# WKUP_CTRL_MMR0_CFG0 register map
Vendor: Texas Instruments
Registers are 32-bit, read-write, reset 0x0 unless marked. A register's access mark holds for its fields unless they carry their own. Offsets are as the file gives them; [hi:lo] are bit positions; {n}, {i} and the like mark numbered series.

## WKUP_CTRL_MMR0_CFG0 (part 2 of 2)
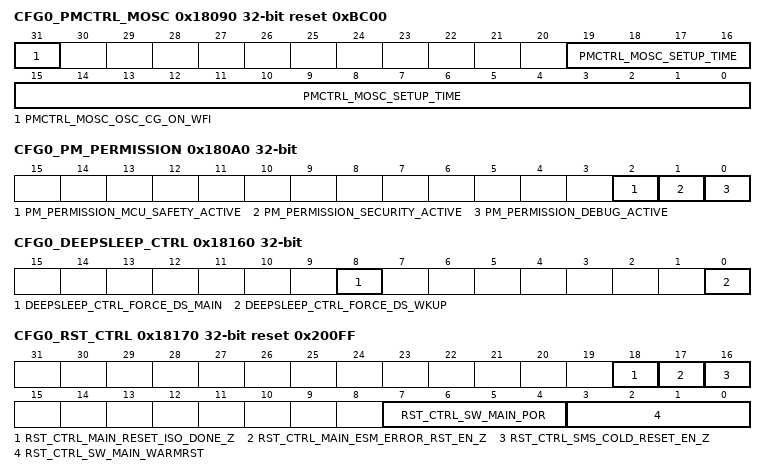
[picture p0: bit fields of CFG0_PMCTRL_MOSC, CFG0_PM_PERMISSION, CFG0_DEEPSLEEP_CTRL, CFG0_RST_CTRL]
0x18090 CFG0_PMCTRL_MOSC reset 0xBC00
  [31] PMCTRL_MOSC_OSC_CG_ON_WFI — When set by Device Manager - the soc clock gating logic will gate the device manager clock once Device Manager has entered the WFI state. (Note: this was named osc_cg_dis but name didn't match function)
  [19:0] PMCTRL_MOSC_SETUP_TIME — Keep the main oscillator clock gates for the number of HFOSC clock cycles This is the time it takes to stabilize the clock source supplier (i.e. Main Oscillator)
0x18098 CFG0_PM_MISC_STATUS ro
  [1:0] PM_MISC_STATUS_OSC_CG_STAT — Reflects the status of the request to clock-gate HF oscillator via MMR PMCTRL_MOSCundefined. 11: osc_cgen_req = '0' & osc_cgen_ack = '1' 10: osc_cgen_req = '1' & osc_cgen_ack = '0' 01: osc_cgen_req = '0' & osc_cgen_ack = '0' 00: osc_cgen_req = '1' & osc_cgen_ack = '1'
0x1809C CFG0_PMCTRL_IO_GLB
  [1:0] PMCTRL_IO_GLB_DSEN_QUALIFIED — To dsen_qualified signal generation logic for daisychain[1:0] logic. Used to control I/O buffer ouput and output activate during deepsleep mode. See IO Integration spec for detail.
0x180A0 CFG0_PM_PERMISSION ro
  [2] PM_PERMISSION_MCU_SAFETY_ACTIVE — Read Only - Reads return a 1 when am62_mcu_ctrl_mmr.wkup_0.RST_MAGIC_WORD_mcu_magic_word_ipcfg[31:0] != 32'h0. When 1, indicates that the MCU is blocking reset and also deep sleep entry.
  [1] PM_PERMISSION_SECURITY_ACTIVE — Read Only - Reads return the value of ms.main_0.sms_iopm_pmpermission_security_active. When 1, indicates that SMS is blocking deep sleep entry.
  [0] PM_PERMISSION_DEBUG_ACTIVE — Read Only - Returns a 1 when IceMelter is blocking deep sleep entry.
0x18160 CFG0_DEEPSLEEP_CTRL
  [8] DEEPSLEEP_CTRL_FORCE_DS_MAIN — Force all MAIN IOs into deepsleep mode when set
  [0] DEEPSLEEP_CTRL_FORCE_DS_WKUP — Force all WKUP IOs into deepsleep mode when set
0x18170 CFG0_RST_CTRL reset 0x200FF
  [18] RST_CTRL_MAIN_RESET_ISO_DONE_Z — Main Domain CPUs can set this bit to block warm reset in the main domain which is useful when the Main domain may be accessing main domain resources (peripherals, memory..). In this case, the main domain cpus will be notified via an interrupt that there is an outstanding warm reset request for the main domain. Once notified, Main needs to finish any outstanding operations in has with main domain resources and then clear this bit. After this bit is cleared, the main domain warm reset will unblocked and the warm reset sequence may continue. 0 - Reset of Main Domain is not Blocked by Main Domain 1 - Reset of Main Domain is Blocked by Main Domain
  [17] RST_CTRL_MAIN_ESM_ERROR_RST_EN_Z — Deactivate Reset of Main by ESM 0 - Activated 1 - Deactivated
  [16] RST_CTRL_SMS_COLD_RESET_EN_Z — Deactivate Reset of Main by SMS 0 - Activated 1 - Deactivated
  [7:4] RST_CTRL_SW_MAIN_POR — Causes Main Domain Power On Reset when set to 4'b0110, Bits will reset to 4'b1111
  [3:0] RST_CTRL_SW_MAIN_WARMRST — Causes Main Domain Warm Reset when set to 4'b0110, Bits will reset to 4'b1111
0x18174 CFG0_RST_STAT ro
  [0] RST_STAT_MCU_RESET_ISO_DONE_Z — is an outstanding warm reset request for the main domain. Once notified, MCU needs to finish any outstanding
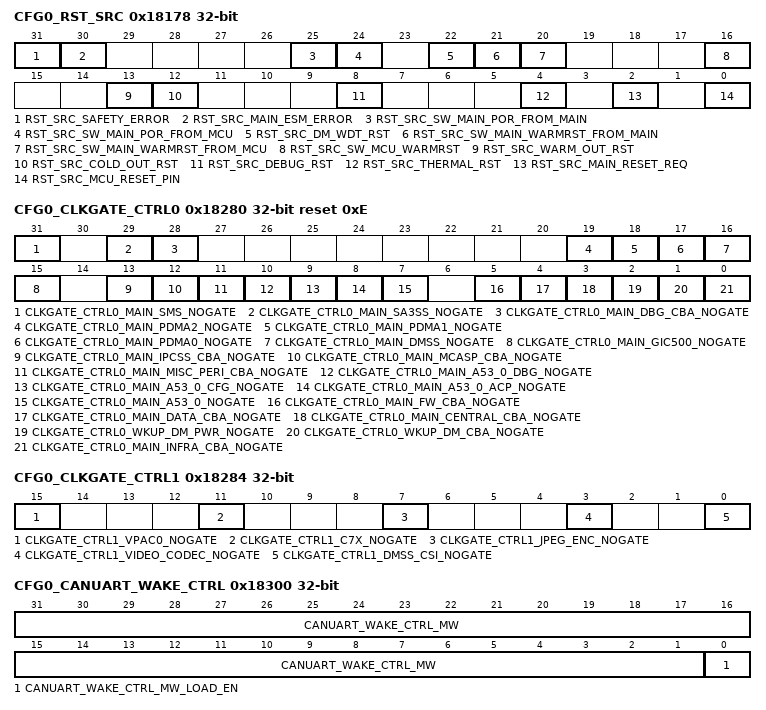
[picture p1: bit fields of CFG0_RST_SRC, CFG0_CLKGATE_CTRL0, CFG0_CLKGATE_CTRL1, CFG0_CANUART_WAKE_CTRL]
0x18178 CFG0_RST_SRC ro
  [31] RST_SRC_SAFETY_ERROR — Reset Caused by MCU ESM Error
  [30] RST_SRC_MAIN_ESM_ERROR — Reset Caused by Main ESM Error
  [25] RST_SRC_SW_MAIN_POR_FROM_MAIN — Software Main Power On Reset From MAIN CTRL MMR
  [24] RST_SRC_SW_MAIN_POR_FROM_MCU — Software Main Power On Reset From MCU CTRL MMR
  [22] RST_SRC_DM_WDT_RST — Watchdog Initiated Reset
  [21] RST_SRC_SW_MAIN_WARMRST_FROM_MAIN — Software Main Warm Reset from MAIN CTRL MMR
  [20] RST_SRC_SW_MAIN_WARMRST_FROM_MCU — Software Main Warm Reset From MCU CTRL MMR
  [16] RST_SRC_SW_MCU_WARMRST — Software Warm Reset
  [13] RST_SRC_WARM_OUT_RST — SMS Warm Reset
  [12] RST_SRC_COLD_OUT_RST — SMS Cold Reset
  [8] RST_SRC_DEBUG_RST — Debug Subsystem Initiated Reset
  [4] RST_SRC_THERMAL_RST — Thermal Reset
  [2] RST_SRC_MAIN_RESET_REQ — Main Reset Pin
  [0] RST_SRC_MCU_RESET_PIN — Rest Caused by MCU Reset Pin
0x1817C CFG0_RST_MAGIC_WORD ro
  [31:0] RST_MAGIC_WORD_MCU_MAGIC_WORD — Magic Word Indicating Status of MCU Subsystem Boot
0x18180 CFG0_WKUP0_EN
  [31:0] WKUP0_EN_WKUPEN — Activates Wakeup from: b0 - WKUP I2C0 b1 - WKUP USART0 b2 - MCU GPIO0 b3 - DEBUG (IceMelter) b4 - Reserved b5 - WKUP DMTIMER0 b6 - WKUP DMTIMER1 b7 - WKUP RTC b8 - Main RESET_REQz b9 - USB0 In Band b10 - USB1 In Band b16 - MAIN IO Daisy Chain b17 - MCU IO Daisy Chain b18 - CANUART IO Daisy Chain
0x18280 CFG0_CLKGATE_CTRL0 reset 0xE
  [31] CLKGATE_CTRL0_MAIN_SMS_NOGATE — MAIN domain SMS (pwr_dis_nogate) clock gate deactivate. 0 - Clocks are gated on idle for power savings 1 - Clocks are not gated on idle, power saving deactivated
  [29] CLKGATE_CTRL0_MAIN_SA3SS_NOGATE — MAIN domain SA3SS clock gate deactivate. 0 - Clocks are gated on idle for power savings 1 - Clocks are not gated on idle, power saving deactivated
  [28] CLKGATE_CTRL0_MAIN_DBG_CBA_NOGATE — MAIN domain Debug CBA (main_dbg_cba)clock gate deactivate. 0 - Clocks are gated on idle for power savings 1 - Clocks are not gated on idle, power saving deactivated
  [19] CLKGATE_CTRL0_MAIN_PDMA2_NOGATE — MAIN domain PDMA2 (pwr_dis_nogate) clock gate deactivate. 0 - Clocks are gated on idle for power savings 1 - Clocks are not gated on idle, power saving deactivated
  [18] CLKGATE_CTRL0_MAIN_PDMA1_NOGATE — MAIN domain PDMA1 (pwr_dis_nogate) clock gate deactivate. 0 - Clocks are gated on idle for power savings 1 - Clocks are not gated on idle, power saving deactivated
  [17] CLKGATE_CTRL0_MAIN_PDMA0_NOGATE — MAIN domain PDMA0 (pwr_dis_nogate) clock gate deactivate. 0 - Clocks are gated on idle for power savings 1 - Clocks are not gated on idle, power saving deactivated
  [16] CLKGATE_CTRL0_MAIN_DMSS_NOGATE — MAIN domain DMSS (pwr_dis_nogate) clock gate deactivate. 0 - Clocks are gated on idle for power savings 1 - Clocks are not gated on idle, power saving deactivated
  [15] CLKGATE_CTRL0_MAIN_GIC500_NOGATE — MAIN A53SS0 (gic500_1_2) clock gate deactivate. 0 - Clocks are gated on idle for power savings 1 - Clocks are not gated on idle, power saving deactivated
  [13] CLKGATE_CTRL0_MAIN_IPCSS_CBA_NOGATE — MAIN domain Infrastructure bus (main_ipcss_cbass) clock gate deactivate. 0 - Clocks are gated on idle for power savings 1 - Clocks are not gated on idle, power saving deactivated
  [12] CLKGATE_CTRL0_MAIN_MCASP_CBA_NOGATE — MAIN domain Infrastructure bus (main_mcasp_cbass) clock gate deactivate. 0 - Clocks are gated on idle for power savings 1 - Clocks are not gated on idle, power saving deactivated
  [11] CLKGATE_CTRL0_MAIN_MISC_PERI_CBA_NOGATE — MAIN domain Infrastructure bus (main_misc_peri_cbass) clock gate deactivate. 0 - Clocks are gated on idle for power savings 1 - Clocks are not gated on idle, power saving deactivated
  [10] CLKGATE_CTRL0_MAIN_A53_0_DBG_NOGATE — MAIN A53SS0 Debug Port clock gate deactivate. 0 - Clocks are gated on idle for power savings 1 - Clocks are not gated on idle, power saving deactivated
  [9] CLKGATE_CTRL0_MAIN_A53_0_CFG_NOGATE — MAIN A53SS0 Configuration Port clock gate deactivate. 0 - Clocks are gated on idle for power savings 1 - Clocks are not gated on idle, power saving deactivated
  [8] CLKGATE_CTRL0_MAIN_A53_0_ACP_NOGATE — MAIN A53SS0 ACP clock gate deactivate. 0 - Clocks are gated on idle for power savings 1 - Clocks are not gated on idle, power saving deactivated
  [7] CLKGATE_CTRL0_MAIN_A53_0_NOGATE — MAIN A53SS0 clock gate deactivate. 0 - Clocks are gated on idle for power savings 1 - Clocks are not gated on idle, power saving deactivated
  [5] CLKGATE_CTRL0_MAIN_FW_CBA_NOGATE — MAIN domain datal bus (main_fw_cbass) clock gate deactivate. 0 - Clocks are gated on idle for power savings 1 - Clocks are not gated on idle, power saving deactivated
  [4] CLKGATE_CTRL0_MAIN_DATA_CBA_NOGATE — MAIN domain data bus (main_cbass) clock gate deactivate. 0 - Clocks are gated on idle for power savings 1 - Clocks are not gated on idle, power saving deactivated
  [3] CLKGATE_CTRL0_MAIN_CENTRAL_CBA_NOGATE — WKUP domain Infrastructure ECC aggregator(wkup_safe_ecc_aggr) clock gate deactivate. 0 - Clocks are gated on idle for power savings 1 - Clocks are not gated on idle, power saving deactivated
  [2] CLKGATE_CTRL0_WKUP_DM_PWR_NOGATE — WKUP domain Device Manager (wkup_dm_pwr_nogate) clock gate deactivate. 0 - Clocks are gated on idle for power savings 1 - Clocks are not gated on idle, power saving deactivated
  [1] CLKGATE_CTRL0_WKUP_DM_CBA_NOGATE — WKUP domain device manager CBA clock gate deactivate. 0 - Clocks are gated on idle for power savings 1 - Clocks are not gated on idle, power saving deactivated
  [0] CLKGATE_CTRL0_MAIN_INFRA_CBA_NOGATE — MAIN domain Infrastructure bus (main_infra_cbass and psc_fw_ch_br) clock gate deactivate. 0 - Clocks are gated on idle for power savings 1 - Clocks are not gated on idle, power saving deactivated
0x18284 CFG0_CLKGATE_CTRL1
  [15] CLKGATE_CTRL1_VPAC0_NOGATE — VPAC0 clock gate deactivate. 0 - Clocks are gated on idle for power savings 1 - Clocks are not gated on idle, power saving deactivated
  [11] CLKGATE_CTRL1_C7X_NOGATE — C7x clock gate deactivate. 0 - Clocks are gated on idle for power savings 1 - Clocks are not gated on idle, power saving deactivated
  [7] CLKGATE_CTRL1_JPEG_ENC_NOGATE — JPEG Encoder clock gate deactivate. 0 - Clocks are gated on idle for power savings 1 - Clocks are not gated on idle, power saving deactivated
  [3] CLKGATE_CTRL1_VIDEO_CODEC_NOGATE — VIDEO CODEC clock gate deactivate. 0 - Clocks are gated on idle for power savings 1 - Clocks are not gated on idle, power saving deactivated
  [0] CLKGATE_CTRL1_DMSS_CSI_NOGATE — DMSS_CSI clock gate deactivate. 0 - Clocks are gated on idle for power savings 1 - Clocks are not gated on idle, power saving deactivated
0x18300 CFG0_CANUART_WAKE_CTRL
  [31:1] CANUART_WAKE_CTRL_MW — CANUART IO magic word. This 31-bit value that activates placing of the CANUART I/Os into isolation for daisy-chain wakeup operation. The Upper 8 bits are software defined. The lower 23 bits are checked by hardware: - 0x5AAAAA - Magic word value to activate isolation whenqualified with mw_load bit - Others - Any other value will prevent isolation when mw_loadtransitions from 0 to 1
  [0] CANUART_WAKE_CTRL_MW_LOAD_EN — Magic word load activate Setting this bit to 1 loads and locks the mw field for CANUART IO isolation. If the mw field matches the magicword value then the value is latched into the CANUART IO voltage domain and CANUART IO isolation is activated. 0 - Unlock and do not load mw value for comparison 1 - Load and lock mw for magic word value comparison
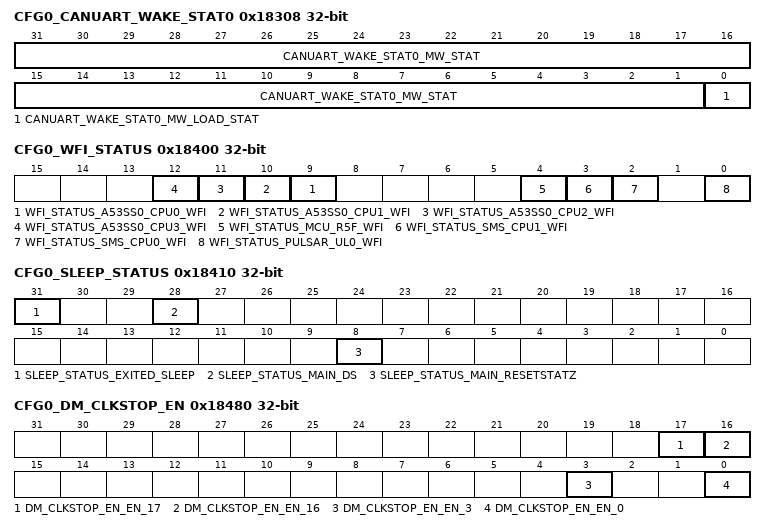
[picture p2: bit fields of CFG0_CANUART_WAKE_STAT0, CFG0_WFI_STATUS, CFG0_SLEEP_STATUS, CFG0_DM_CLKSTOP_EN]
0x18308 CFG0_CANUART_WAKE_STAT0 ro
  [31:1] CANUART_WAKE_STAT0_MW_STAT — CANUART magic word status Indicates the latched value of the mw field.
  [0] CANUART_WAKE_STAT0_MW_LOAD_STAT — Magic word load status. Indicates the latched value of the mw_load_en bit
0x1830C CFG0_CANUART_WAKE_STAT1 ro
  [0] CANUART_WAKE_STAT1_CANUART_IO_MODE — Indicates if CANUART IO wakeup mode is activated. 0 - Not activated (load_en not set or mw doesn't match magic word) 1 - CANUART IO mode activated
0x18310 CFG0_CANUART_WAKE_OFF_MODE
  [31:0] CANUART_WAKE_OFF_MODE_MW — magic word
0x18318 CFG0_CANUART_WAKE_OFF_MODE_STAT ro
  [31:0] CANUART_WAKE_OFF_MODE_STAT_MW — returned magic word
0x18320 CFG0_CANUART_WAKE_RESUME_KEY
  [31:0] KEYVAL — key value
0x18340 CFG0_CANUART_WAKE_RESUME_KEY_STAT ro
  [31:0] KEYVAL — returned key value
0x18400 CFG0_WFI_STATUS ro
  [n+9] WFI_STATUS_A53SS0_CPU{n}_WFI (n=0..3) — WFI status of A53SS0 CPU{n}
  [4] WFI_STATUS_MCU_R5F_WFI — WFI status of MCU Cortex R5F
  [3] WFI_STATUS_SMS_CPU1_WFI — WFI status of SMS Cortex M4F1
  [2] WFI_STATUS_SMS_CPU0_WFI — WFI status of SMS Cortex M4F0
  [0] WFI_STATUS_PULSAR_UL0_WFI — WFI status of Device Manager Cortex R5F
0x18410 CFG0_SLEEP_STATUS access not given
  [31] SLEEP_STATUS_EXITED_SLEEP — Set when the HFXOSC clock gate is activated (rising edge capture of OSC_CG_ACK). To be read and cleared by DM after exiting WFI as a status signal distinguishing the case where WFI was entered and the clock was stopped, then exited with a wakeup (this bit will be set) from the case where an interrupt or other event caused the WFI sequence to stop and the HFXOSC was never stopped. (access R/W1TC)
  [28] SLEEP_STATUS_MAIN_DS — Set when the main domain deep sleep power on reset / power domain off is activated. (rising edge detect of am62_wkup_ctrl_mmr.wkup_0.DS_MAIN_por_pdoff_ft_out_ipcfg). This will be checked by the ROM on TIFS upon exiting from reset to determine if it is a power on reset or exiting deep sleep. (access R/W1TC)
  [8] SLEEP_STATUS_MAIN_RESETSTATZ ro — Reflects the status of the main domain resetz signal Field values (others are reserved): 1'b0 - Main Domain In Reset 1'b1 - Main Domain Out of Reset
0x18418 CFG0_DS_MAGIC_WORD
  [31:0] DS_MAGIC_WORD_DS_MAGIC_WORD — Magic Word Indicating State of Deep Sleep
0x18420 CFG0_DS_MAIN reset 0xF
  [3:0] DS_MAIN_POR_PDOFF — Signal Puts main SMS, DebugSS and MainIP Power Domains into Power Off state, and asserts Main Power On Reset. Field values (others are reserved): 4'b0110 - Off 4'b1111 - On
0x18440 CFG0_DS_DM_RESET reset 0xF
  [3:0] DS_DM_RESET_MASK — Signal used to mask main domain resets from Device Manager / Wakeup and MCU Ips Field values (others are reserved): 4'b0110 - Masked 4'b1111 - UnMasked
0x18460 CFG0_DS_USB0_RESET reset 0xF
  [3:0] DS_USB0_RESET_MASK — Signal used to block reset to the USBSS0 Field values (others are reserved): 4'b0110 - Masked 4'b1111 - UnMasked
0x18464 CFG0_DS_USB1_RESET reset 0xF
  [3:0] DS_USB1_RESET_MASK — Signal used to block reset to the USBSS1 Field values (others are reserved): 4'b0110 - Masked 4'b1111 - UnMasked
0x18480 CFG0_DM_CLKSTOP_EN
  [17] DM_CLKSTOP_EN_EN_17 — WKUP DMTIMER1 Participation in Clockstop Req Group Field values (others are reserved): 1'b0 - Not Participating in Clockstop Override Group. DM_CLKSTOP_ACK.17 always reads '1' 1'b1 - Participating in Clockstop Override Group. DM_CLKSTOP_ACK.17 reflects the IP clockstop_ack
  [16] DM_CLKSTOP_EN_EN_16 — WKUP DMTIMER0 Participation in Clockstop Req Group Field values (others are reserved): 1'b0 - Not Participating in Clockstop Override Group. DM_CLKSTOP_ACK.16 always reads '1' 1'b1 - Participating in Clockstop Override Group. DM_CLKSTOP_ACK.16 reflects the IP clockstop_ack
  [3] DM_CLKSTOP_EN_EN_3 — WKUP UART0 Participation in Clockstop Req Group Field values (others are reserved): 1'b0 - Not Participating in Clockstop Override Group. DM_CLKSTOP_ACK.3 always reads '1' 1'b1 - Participating in Clockstop Override Group. DM_CLKSTOP_ACK.3 reflects the IP clockstop_ack
  [0] DM_CLKSTOP_EN_EN_0 — WKUP I2C0 Participation in Clockstop Req Group Field values (others are reserved): 1'b0 - Not Participating in Clockstop Override Group. DM_CLKSTOP_ACK.0 always reads '1' 1'b1 - Participating in Clockstop Override Group. DM_CLKSTOP_ACK.0 reflects the IP clockstop_ack
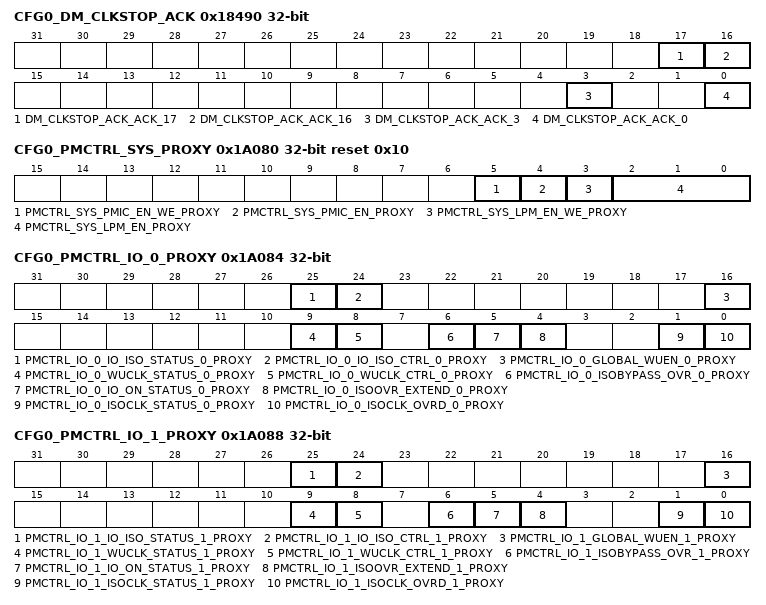
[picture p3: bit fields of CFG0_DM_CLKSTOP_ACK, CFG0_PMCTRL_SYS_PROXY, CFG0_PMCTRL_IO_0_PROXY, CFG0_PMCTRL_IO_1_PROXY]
0x18490 CFG0_DM_CLKSTOP_ACK ro
  [17] DM_CLKSTOP_ACK_ACK_17 — WKUP DMTIMER1 Clockstop Ack Status Field values (others are reserved): 1'b0 - IP is Participating in Clockstop Override Group, and IP clockstop_ack is 0 1'b1 - IP Is either not Participating in Clockstop Override Group, or IP has returned IP clockstop_ack
  [16] DM_CLKSTOP_ACK_ACK_16 — WKUP DMTIMER0 Clockstop Ack Status Field values (others are reserved): 1'b0 - IP is Participating in Clockstop Override Group, and IP clockstop_ack is 0 1'b1 - IP Is either not Participating in Clockstop Override Group, or IP has returned IP clockstop_ack
  [3] DM_CLKSTOP_ACK_ACK_3 — WKUP UART0 Clockstop Ack Status Field values (others are reserved): 1'b0 - IP is Participating in Clockstop Override Group, and IP clockstop_ack is 0 1'b1 - IP Is either not Participating in Clockstop Override Group, or IP has returned IP clockstop_ack
  [0] DM_CLKSTOP_ACK_ACK_0 — WKUP I2C0 Clockstop Ack Status Field values (others are reserved): 1'b0 - IP is Participating in Clockstop Override Group, and IP clockstop_ack is 0 1'b1 - IP Is either not Participating in Clockstop Override Group, or IP has returned IP clockstop_ack
0x184A0 CFG0_DM_GRP_CLKSTOP_REQ
  [0] DM_GRP_CLKSTOP_REQ_REQ — Assertion of Clockstop Req to IPs participating in Clockstop Req Group Field values (others are reserved): 1'b0 - Deassert CLKSTOP Req to all IPs participating in Clockstop Override Group 1'b1 - Assert CLKSTOP Req to all IPs participating in Clockstop Override Group
0x184A4 CFG0_DM_GRP_CLKSTOP_ACK ro
  [0] DM_GRP_CLKSTOP_ACK_ACK — Status of IPs Participating in Clockstop Ack Group. If DM_CLKSTOP_EN is 0 (no IPs participating) this bit always reads 1. Field values (others are reserved): 1'b0 - At least one IP participating in Clockstop Override has not returned Ack 1'b1 - All IPs that are participating in Clockstop Override have returned Ack
0x18500 CFG0_DEVICE_TYPE ro
  [7:4] DEVICE_TYPE_SMS_DEV_TYPE
{0x19100+4i} CFG0_CLAIMREG_P6_R{i}_READONLY ro (i=0..10)
  [31:0] CLAIMREG_P6_R{i}_READONLY — Claim bits for Partition 6
0x1A040 CFG0_FW_CTRL_OUT0_PROXY
  [31:0] FW_CTRL_OUT0_FW_CTRL_OUT0_PROXY
0x1A044 CFG0_FW_CTRL_OUT0_SET_PROXY access not given reset not defined
0x1A048 CFG0_FW_CTRL_OUT0_CLR_PROXY access not given reset not defined
0x1A04C CFG0_FW_STS_IN0_PROXY access not given reset not defined
0x1A050 CFG0_FW_CTRL_OUT1_PROXY access not given reset not defined
0x1A054 CFG0_FW_CTRL_OUT1_SET_PROXY access not given reset not defined
0x1A058 CFG0_FW_CTRL_OUT1_CLR_PROXY access not given reset not defined
0x1A05C CFG0_FW_STS_IN1_PROXY access not given reset not defined
0x1A080 CFG0_PMCTRL_SYS_PROXY reset 0x10
  [5] PMCTRL_SYS_PMIC_EN_WE_PROXY — Unused Field - Value is Don't Care
  [4] PMCTRL_SYS_PMIC_EN_PROXY — Controls state of PMIC_LPM_EN_OUT when LPM_EN[2:0] is 000
  [3] PMCTRL_SYS_LPM_EN_WE_PROXY — Unused Field - Value is Don't Care
  [2:0] PMCTRL_SYS_LPM_EN_PROXY — Controls whether PMIC_LPM_EN_OUT is driven by the pmic_en bit, or by deep sleep logic. Field values (others are reserved): 3'b000 - PMIC_LPM_EN_OUT controlled by pmic_en bit. 3'b101 - PMIC_LPM_EN_OUT controlled by DeepSleep Logic
0x1A084 CFG0_PMCTRL_IO_0_PROXY access per field
  [25] PMCTRL_IO_0_IO_ISO_STATUS_0_PROXY ro — IO ISO Status. Read 0: IO isolation not active. Read 1: IO isolation active. Reflects value of DM input port io_isoack coming back from IO pad ring.
  [24] PMCTRL_IO_0_IO_ISO_CTRL_0_PROXY rw — IO ISO control. Writing this bit to 1 will kick off IO isolation.
  [16] PMCTRL_IO_0_GLOBAL_WUEN_0_PROXY rw — Global IO wakeup activate. This is a gating condition to all individual IO WUEN coming from control module. Gating is done in the Spinner logic. 0:All individual IO WUEN are gated in the Spinner logic (override to 0). 1: All individual IO WUEN from control module are going to Ios. Map to DM input port io_globalwkupen
  [9] PMCTRL_IO_0_WUCLK_STATUS_0_PROXY ro — Reflects value of DM input port io_wuclkack coming back from IO pad ring.
  [8] PMCTRL_IO_0_WUCLK_CTRL_0_PROXY rw — Direct control on WUCLKIN signal to IO pad ring.0:WUCLKIN signal is driven to 0.IO wakeup daisy chain is functional as well as IO whose wakeup feature is activated. 1:WUCLKIN signal is driven to 1. IO wakeup daisy chain is reset and is latching current pad states and WUEN inputs.
  [6] PMCTRL_IO_0_ISOBYPASS_OVR_0_PROXY rw — This MMR bit drives directly DM output port io_isobypassundefined.
  [5] PMCTRL_IO_0_IO_ON_STATUS_0_PROXY ro — Gives the functional status of the IO ring. Read 0: Part or all of the Ios are not in the ON state that is are in isolation state. Read 1: All Ios are in the ON state. io_on_status = assign 1 if (io_iso == 0 & io_isoack==0 & io_iso_clk == 0 & io_isoclk_ack = 0 ) else 0;
  [4] PMCTRL_IO_0_ISOOVR_EXTEND_0_PROXY rw — This drives the SOC chain ISO-OVERRIDE global control. This bit drives directly the DM output port io_isoovrundefined. At the SOC level it is used to activate when 1 or gate-off when 0, the individual ISOOR for each IO. This operates as a global activate/deactivate for the individual IOs.Control for IO isolation extension. '0' IO isolation is not extended. Transition happens as soon as automatic restore is completed. '1' IO isolation is extended. The IOs whose ISOOVR bits have been individually set in their PADCFG MMRs will all get its IO isolation extended beyond the point when the initial IO daisy chain isolation is released.
  [1] PMCTRL_IO_0_ISOCLK_STATUS_0_PROXY ro — Reflects value of DM input port io_isoclkack coming back from IO pad ring.
  [0] PMCTRL_IO_0_ISOCLK_OVRD_0_PROXY rw — Override control on ISOCLKIN signal to IO pad ring. When not overridden this signal is controlled by hardware only. 0 ISOCLKIN signal is not override. 1 ISOCLKIN signal is overridden to active value ('1').
0x1A088 CFG0_PMCTRL_IO_1_PROXY access per field
  [25] PMCTRL_IO_1_IO_ISO_STATUS_1_PROXY ro — IO ISO Status. Read 0: IO isolation not active. Read 1: IO isolation active. Reflects value of DM input port io_isoack coming back from IO pad ring.
  [24] PMCTRL_IO_1_IO_ISO_CTRL_1_PROXY rw — IO ISO control. Writing this bit to 1 will kick off IO isolation.
  [16] PMCTRL_IO_1_GLOBAL_WUEN_1_PROXY rw — Global IO wakeup activate. This is a gating condition to all individual IO WUEN coming from control module. Gating is done in the Spinner logic. 0:All individual IO WUEN are gated in the Spinner logic (override to 0). 1: All individual IO WUEN from control module are going to Ios. Map to DM input port io_globalwkupen
  [9] PMCTRL_IO_1_WUCLK_STATUS_1_PROXY ro — Reflects value of DM input port io_wuclkack coming back from IO pad ring.
  [8] PMCTRL_IO_1_WUCLK_CTRL_1_PROXY rw — Direct control on WUCLKIN signal to IO pad ring.0:WUCLKIN signal is driven to 0.IO wakeup daisy chain is functional as well as IO whose wakeup feature is activated. 1:WUCLKIN signal is driven to 1. IO wakeup daisy chain is reset and is latching current pad states and WUEN inputs.
  [6] PMCTRL_IO_1_ISOBYPASS_OVR_1_PROXY rw — This MMR bit drives directly DM output port io_isobypassundefined.
  [5] PMCTRL_IO_1_IO_ON_STATUS_1_PROXY ro — Gives the functional status of the IO ring. Read 0: Part or all of the Ios are not in the ON state that is are in isolation state. Read 1: All Ios are in the ON state. io_on_status = assign 1 if (io_iso == 0 & io_isoack==0 & io_iso_clk == 0 & io_isoclk_ack = 0 ) else 0;
  [4] PMCTRL_IO_1_ISOOVR_EXTEND_1_PROXY rw — This drives the SOC chain ISO-OVERRIDE global control. This bit drives directly the DM output port io_isoovrundefined. At the SOC level it is used to activate when 1 or gate-off when 0, the individual ISOOR for each IO. This operates as a global activate/deactivate for the individual IOs.Control for IO isolation extension. '0' IO isolation is not extended. Transition happens as soon as automatic restore is completed. '1' IO isolation is extended. The IOs whose ISOOVR bits have been individually set in their PADCFG MMRs will all get its IO isolation extended beyond the point when the initial IO daisy chain isolation is released.
  [1] PMCTRL_IO_1_ISOCLK_STATUS_1_PROXY ro — Reflects value of DM input port io_isoclkack coming back from IO pad ring.
  [0] PMCTRL_IO_1_ISOCLK_OVRD_1_PROXY rw — Override control on ISOCLKIN signal to IO pad ring. When not overridden this signal is controlled by hardware only. 0 ISOCLKIN signal is not override. 1 ISOCLKIN signal is overridden to active value ('1').
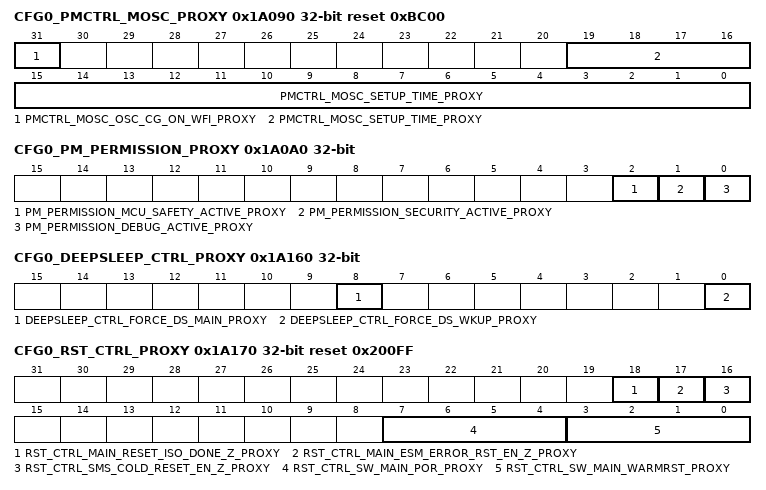
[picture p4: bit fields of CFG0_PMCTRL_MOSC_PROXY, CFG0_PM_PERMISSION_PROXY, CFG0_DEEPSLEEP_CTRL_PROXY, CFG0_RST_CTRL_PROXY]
0x1A090 CFG0_PMCTRL_MOSC_PROXY reset 0xBC00
  [31] PMCTRL_MOSC_OSC_CG_ON_WFI_PROXY — When set by Device Manager - the soc clock gating logic will gate the device manager clock once Device Manager has entered the WFI state. (Note: this was named osc_cg_dis but name didn't match function)
  [19:0] PMCTRL_MOSC_SETUP_TIME_PROXY — Keep the main oscillator clock gates for the number of HFOSC clock cycles This is the time it takes to stabilize the clock source supplier (i.e. Main Oscillator)
0x1A098 CFG0_PM_MISC_STATUS_PROXY ro
  [1:0] PM_MISC_STATUS_OSC_CG_STAT_PROXY — Reflects the status of the request to clock-gate HF oscillator via MMR PMCTRL_MOSCundefined. 11: osc_cgen_req = '0' & osc_cgen_ack = '1' 10: osc_cgen_req = '1' & osc_cgen_ack = '0' 01: osc_cgen_req = '0' & osc_cgen_ack = '0' 00: osc_cgen_req = '1' & osc_cgen_ack = '1'
0x1A09C CFG0_PMCTRL_IO_GLB_PROXY
  [1:0] PMCTRL_IO_GLB_DSEN_QUALIFIED_PROXY — To dsen_qualified signal generation logic for daisychain[1:0] logic. Used to control I/O buffer ouput and output activate during deepsleep mode. See IO Integration spec for detail.
0x1A0A0 CFG0_PM_PERMISSION_PROXY ro
  [2] PM_PERMISSION_MCU_SAFETY_ACTIVE_PROXY — Read Only - Reads return a 1 when am62_mcu_ctrl_mmr.wkup_0.RST_MAGIC_WORD_mcu_magic_word_ipcfg[31:0] != 32'h0. When 1, indicates that the MCU is blocking reset and also deep sleep entry.
  [1] PM_PERMISSION_SECURITY_ACTIVE_PROXY — Read Only - Reads return the value of ms.main_0.sms_iopm_pmpermission_security_active. When 1, indicates that SMS is blocking deep sleep entry.
  [0] PM_PERMISSION_DEBUG_ACTIVE_PROXY — Read Only - Returns a 1 when IceMelter is blocking deep sleep entry.
0x1A160 CFG0_DEEPSLEEP_CTRL_PROXY
  [8] DEEPSLEEP_CTRL_FORCE_DS_MAIN_PROXY — Force all MAIN IOs into deepsleep mode when set
  [0] DEEPSLEEP_CTRL_FORCE_DS_WKUP_PROXY — Force all WKUP IOs into deepsleep mode when set
0x1A170 CFG0_RST_CTRL_PROXY reset 0x200FF
  [18] RST_CTRL_MAIN_RESET_ISO_DONE_Z_PROXY — Main Domain CPUs can set this bit to block warm reset in the main domain which is useful when the Main domain may be accessing main domain resources (peripherals, memory..). In this case, the main domain cpus will be notified via an interrupt that there is an outstanding warm reset request for the main domain. Once notified, Main needs to finish any outstanding operations in has with main domain resources and then clear this bit. After this bit is cleared, the main domain warm reset will unblocked and the warm reset sequence may continue. 0 - Reset of Main Domain is not Blocked by Main Domain 1 - Reset of Main Domain is Blocked by Main Domain
  [17] RST_CTRL_MAIN_ESM_ERROR_RST_EN_Z_PROXY — Deactivate Reset of Main by ESM 0 - Activated 1 - Deactivated
  [16] RST_CTRL_SMS_COLD_RESET_EN_Z_PROXY — Deactivate Reset of Main by SMS 0 - Activated 1 - Deactivated
  [7:4] RST_CTRL_SW_MAIN_POR_PROXY — Causes Main Domain Power On Reset when set to 4'b0110, Bits will reset to 4'b1111
  [3:0] RST_CTRL_SW_MAIN_WARMRST_PROXY — Causes Main Domain Warm Reset when set to 4'b0110, Bits will reset to 4'b1111
0x1A174 CFG0_RST_STAT_PROXY ro
  [0] RST_STAT_MCU_RESET_ISO_DONE_Z_PROXY — is an outstanding warm reset request for the main domain. Once notified, MCU needs to finish any outstanding
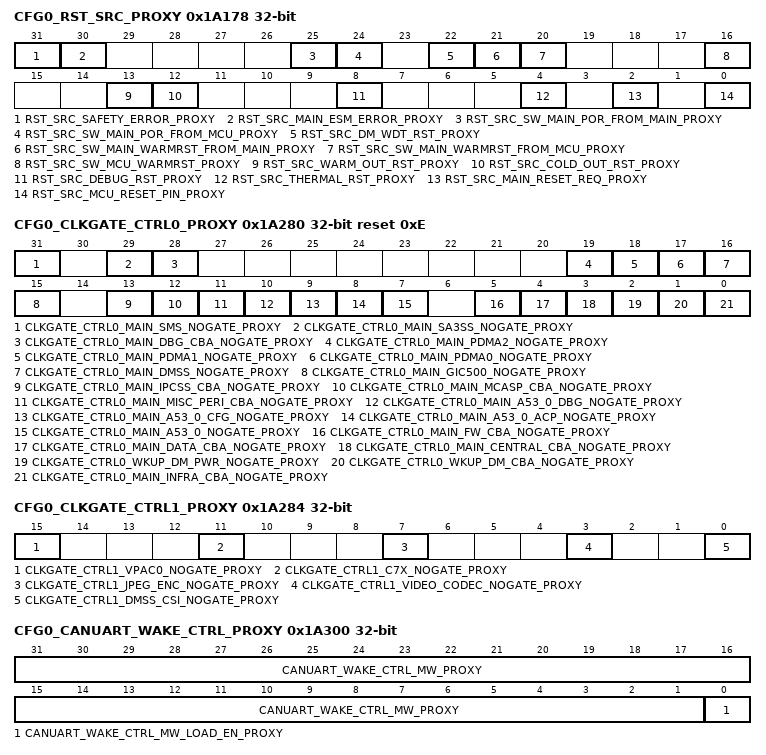
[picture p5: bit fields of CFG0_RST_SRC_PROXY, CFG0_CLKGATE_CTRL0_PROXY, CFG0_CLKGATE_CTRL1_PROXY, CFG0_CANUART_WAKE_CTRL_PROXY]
0x1A178 CFG0_RST_SRC_PROXY ro
  [31] RST_SRC_SAFETY_ERROR_PROXY — Reset Caused by MCU ESM Error
  [30] RST_SRC_MAIN_ESM_ERROR_PROXY — Reset Caused by Main ESM Error
  [25] RST_SRC_SW_MAIN_POR_FROM_MAIN_PROXY — Software Main Power On Reset From MAIN CTRL MMR
  [24] RST_SRC_SW_MAIN_POR_FROM_MCU_PROXY — Software Main Power On Reset From MCU CTRL MMR
  [22] RST_SRC_DM_WDT_RST_PROXY — Watchdog Initiated Reset
  [21] RST_SRC_SW_MAIN_WARMRST_FROM_MAIN_PROXY — Software Main Warm Reset from MAIN CTRL MMR
  [20] RST_SRC_SW_MAIN_WARMRST_FROM_MCU_PROXY — Software Main Warm Reset From MCU CTRL MMR
  [16] RST_SRC_SW_MCU_WARMRST_PROXY — Software Warm Reset
  [13] RST_SRC_WARM_OUT_RST_PROXY — SMS Warm Reset
  [12] RST_SRC_COLD_OUT_RST_PROXY — SMS Cold Reset
  [8] RST_SRC_DEBUG_RST_PROXY — Debug Subsystem Initiated Reset
  [4] RST_SRC_THERMAL_RST_PROXY — Thermal Reset
  [2] RST_SRC_MAIN_RESET_REQ_PROXY — Main Reset Pin
  [0] RST_SRC_MCU_RESET_PIN_PROXY — Rest Caused by MCU Reset Pin
0x1A17C CFG0_RST_MAGIC_WORD_PROXY ro
  [31:0] RST_MAGIC_WORD_MCU_MAGIC_WORD_PROXY — Magic Word Indicating Status of MCU Subsystem Boot
0x1A180 CFG0_WKUP0_EN_PROXY
  [31:0] WKUP0_EN_WKUPEN_PROXY — Activates Wakeup from: b0 - WKUP I2C0 b1 - WKUP USART0 b2 - MCU GPIO0 b3 - DEBUG (IceMelter) b4 - Reserved b5 - WKUP DMTIMER0 b6 - WKUP DMTIMER1 b7 - WKUP RTC b8 - Main RESET_REQz b9 - USB0 In Band b10 - USB1 In Band b16 - MAIN IO Daisy Chain b17 - MCU IO Daisy Chain b18 - CANUART IO Daisy Chain
0x1A280 CFG0_CLKGATE_CTRL0_PROXY reset 0xE
  [31] CLKGATE_CTRL0_MAIN_SMS_NOGATE_PROXY — MAIN domain SMS (pwr_dis_nogate) clock gate deactivate. 0 - Clocks are gated on idle for power savings 1 - Clocks are not gated on idle, power saving deactivated
  [29] CLKGATE_CTRL0_MAIN_SA3SS_NOGATE_PROXY — MAIN domain SA3SS clock gate deactivate. 0 - Clocks are gated on idle for power savings 1 - Clocks are not gated on idle, power saving deactivated
  [28] CLKGATE_CTRL0_MAIN_DBG_CBA_NOGATE_PROXY — MAIN domain Debug CBA (main_dbg_cba)clock gate deactivate. 0 - Clocks are gated on idle for power savings 1 - Clocks are not gated on idle, power saving deactivated
  [19] CLKGATE_CTRL0_MAIN_PDMA2_NOGATE_PROXY — MAIN domain PDMA2 (pwr_dis_nogate) clock gate deactivate. 0 - Clocks are gated on idle for power savings 1 - Clocks are not gated on idle, power saving deactivated
  [18] CLKGATE_CTRL0_MAIN_PDMA1_NOGATE_PROXY — MAIN domain PDMA1 (pwr_dis_nogate) clock gate deactivate. 0 - Clocks are gated on idle for power savings 1 - Clocks are not gated on idle, power saving deactivated
  [17] CLKGATE_CTRL0_MAIN_PDMA0_NOGATE_PROXY — MAIN domain PDMA0 (pwr_dis_nogate) clock gate deactivate. 0 - Clocks are gated on idle for power savings 1 - Clocks are not gated on idle, power saving deactivated
  [16] CLKGATE_CTRL0_MAIN_DMSS_NOGATE_PROXY — MAIN domain DMSS (pwr_dis_nogate) clock gate deactivate. 0 - Clocks are gated on idle for power savings 1 - Clocks are not gated on idle, power saving deactivated
  [15] CLKGATE_CTRL0_MAIN_GIC500_NOGATE_PROXY — MAIN A53SS0 (gic500_1_2) clock gate deactivate. 0 - Clocks are gated on idle for power savings 1 - Clocks are not gated on idle, power saving deactivated
  [13] CLKGATE_CTRL0_MAIN_IPCSS_CBA_NOGATE_PROXY — MAIN domain Infrastructure bus (main_ipcss_cbass) clock gate deactivate. 0 - Clocks are gated on idle for power savings 1 - Clocks are not gated on idle, power saving deactivated
  [12] CLKGATE_CTRL0_MAIN_MCASP_CBA_NOGATE_PROXY — MAIN domain Infrastructure bus (main_mcasp_cbass) clock gate deactivate. 0 - Clocks are gated on idle for power savings 1 - Clocks are not gated on idle, power saving deactivated
  [11] CLKGATE_CTRL0_MAIN_MISC_PERI_CBA_NOGATE_PROXY — MAIN domain Infrastructure bus (main_misc_peri_cbass) clock gate deactivate. 0 - Clocks are gated on idle for power savings 1 - Clocks are not gated on idle, power saving deactivated
  [10] CLKGATE_CTRL0_MAIN_A53_0_DBG_NOGATE_PROXY — MAIN A53SS0 Debug Port clock gate deactivate. 0 - Clocks are gated on idle for power savings 1 - Clocks are not gated on idle, power saving deactivated
  [9] CLKGATE_CTRL0_MAIN_A53_0_CFG_NOGATE_PROXY — MAIN A53SS0 Configuration Port clock gate deactivate. 0 - Clocks are gated on idle for power savings 1 - Clocks are not gated on idle, power saving deactivated
  [8] CLKGATE_CTRL0_MAIN_A53_0_ACP_NOGATE_PROXY — MAIN A53SS0 ACP clock gate deactivate. 0 - Clocks are gated on idle for power savings 1 - Clocks are not gated on idle, power saving deactivated
  [7] CLKGATE_CTRL0_MAIN_A53_0_NOGATE_PROXY — MAIN A53SS0 clock gate deactivate. 0 - Clocks are gated on idle for power savings 1 - Clocks are not gated on idle, power saving deactivated
  [5] CLKGATE_CTRL0_MAIN_FW_CBA_NOGATE_PROXY — MAIN domain datal bus (main_fw_cbass) clock gate deactivate. 0 - Clocks are gated on idle for power savings 1 - Clocks are not gated on idle, power saving deactivated
  [4] CLKGATE_CTRL0_MAIN_DATA_CBA_NOGATE_PROXY — MAIN domain data bus (main_cbass) clock gate deactivate. 0 - Clocks are gated on idle for power savings 1 - Clocks are not gated on idle, power saving deactivated
  [3] CLKGATE_CTRL0_MAIN_CENTRAL_CBA_NOGATE_PROXY — WKUP domain Infrastructure ECC aggregator(wkup_safe_ecc_aggr) clock gate deactivate. 0 - Clocks are gated on idle for power savings 1 - Clocks are not gated on idle, power saving deactivated
  [2] CLKGATE_CTRL0_WKUP_DM_PWR_NOGATE_PROXY — WKUP domain Device Manager (wkup_dm_pwr_nogate) clock gate deactivate. 0 - Clocks are gated on idle for power savings 1 - Clocks are not gated on idle, power saving deactivated
  [1] CLKGATE_CTRL0_WKUP_DM_CBA_NOGATE_PROXY — WKUP domain device manager CBA clock gate deactivate. 0 - Clocks are gated on idle for power savings 1 - Clocks are not gated on idle, power saving deactivated
  [0] CLKGATE_CTRL0_MAIN_INFRA_CBA_NOGATE_PROXY — MAIN domain Infrastructure bus (main_infra_cbass and psc_fw_ch_br) clock gate deactivate. 0 - Clocks are gated on idle for power savings 1 - Clocks are not gated on idle, power saving deactivated
0x1A284 CFG0_CLKGATE_CTRL1_PROXY
  [15] CLKGATE_CTRL1_VPAC0_NOGATE_PROXY — VPAC0 clock gate deactivate. 0 - Clocks are gated on idle for power savings 1 - Clocks are not gated on idle, power saving deactivated
  [11] CLKGATE_CTRL1_C7X_NOGATE_PROXY — C7x clock gate deactivate. 0 - Clocks are gated on idle for power savings 1 - Clocks are not gated on idle, power saving deactivated
  [7] CLKGATE_CTRL1_JPEG_ENC_NOGATE_PROXY — JPEG Encoder clock gate deactivate. 0 - Clocks are gated on idle for power savings 1 - Clocks are not gated on idle, power saving deactivated
  [3] CLKGATE_CTRL1_VIDEO_CODEC_NOGATE_PROXY — VIDEO CODEC clock gate deactivate. 0 - Clocks are gated on idle for power savings 1 - Clocks are not gated on idle, power saving deactivated
  [0] CLKGATE_CTRL1_DMSS_CSI_NOGATE_PROXY — DMSS_CSI clock gate deactivate. 0 - Clocks are gated on idle for power savings 1 - Clocks are not gated on idle, power saving deactivated
0x1A300 CFG0_CANUART_WAKE_CTRL_PROXY
  [31:1] CANUART_WAKE_CTRL_MW_PROXY — CANUART IO magic word. This 31-bit value that activates placing of the CANUART I/Os into isolation for daisy-chain wakeup operation. The Upper 8 bits are software defined. The lower 23 bits are checked by hardware: - 0x5AAAAA - Magic word value to activate isolation whenqualified with mw_load bit - Others - Any other value will prevent isolation when mw_loadtransitions from 0 to 1
  [0] CANUART_WAKE_CTRL_MW_LOAD_EN_PROXY — Magic word load activate Setting this bit to 1 loads and locks the mw field for CANUART IO isolation. If the mw field matches the magicword value then the value is latched into the CANUART IO voltage domain and CANUART IO isolation is activated. 0 - Unlock and do not load mw value for comparison 1 - Load and lock mw for magic word value comparison
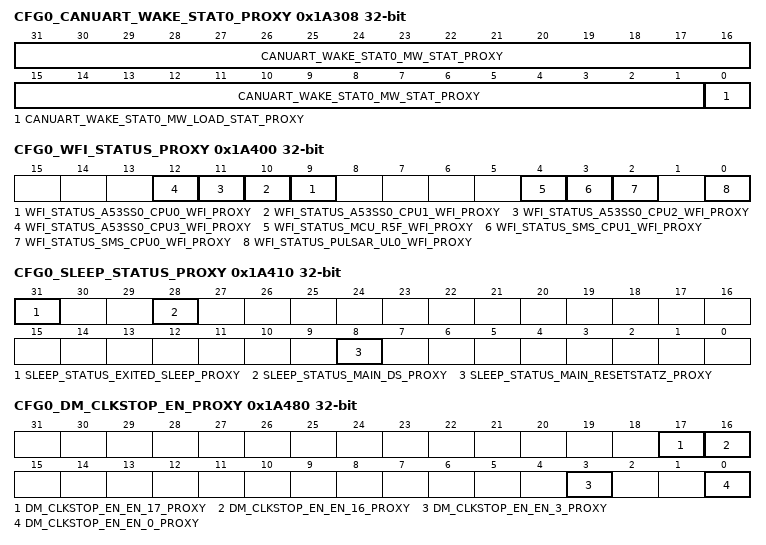
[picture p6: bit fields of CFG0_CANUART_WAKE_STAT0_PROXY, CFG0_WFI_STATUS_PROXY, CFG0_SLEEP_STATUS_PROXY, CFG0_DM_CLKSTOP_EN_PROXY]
0x1A308 CFG0_CANUART_WAKE_STAT0_PROXY ro
  [31:1] CANUART_WAKE_STAT0_MW_STAT_PROXY — CANUART magic word status Indicates the latched value of the mw field.
  [0] CANUART_WAKE_STAT0_MW_LOAD_STAT_PROXY — Magic word load status. Indicates the latched value of the mw_load_en bit
0x1A30C CFG0_CANUART_WAKE_STAT1_PROXY ro
  [0] CANUART_WAKE_STAT1_CANUART_IO_MODE_PROXY — Indicates if CANUART IO wakeup mode is activated. 0 - Not activated (load_en not set or mw doesn't match magic word) 1 - CANUART IO mode activated
0x1A310 CFG0_CANUART_WAKE_OFF_MODE_PROXY
  [31:0] CANUART_WAKE_OFF_MODE_MW_PROXY — magic word
0x1A318 CFG0_CANUART_WAKE_OFF_MODE_STAT_PROXY ro
  [31:0] CANUART_WAKE_OFF_MODE_STAT_MW_PROXY — returned magic word
0x1A320 CFG0_CANUART_WAKE_RESUME_KEY_PROXY
  [31:0] KEYVAL_PROXY — key value
0x1A340 CFG0_CANUART_WAKE_RESUME_KEY_STAT_PROXY ro
  [31:0] KEYVAL_PROXY — returned key value
0x1A400 CFG0_WFI_STATUS_PROXY ro
  [n+9] WFI_STATUS_A53SS0_CPU{n}_WFI_PROXY (n=0..3) — WFI status of A53SS0 CPU{n}
  [4] WFI_STATUS_MCU_R5F_WFI_PROXY — WFI status of MCU Cortex R5F
  [3] WFI_STATUS_SMS_CPU1_WFI_PROXY — WFI status of SMS Cortex M4F1
  [2] WFI_STATUS_SMS_CPU0_WFI_PROXY — WFI status of SMS Cortex M4F0
  [0] WFI_STATUS_PULSAR_UL0_WFI_PROXY — WFI status of Device Manager Cortex R5F
0x1A410 CFG0_SLEEP_STATUS_PROXY access not given
  [31] SLEEP_STATUS_EXITED_SLEEP_PROXY — Set when the HFXOSC clock gate is activated (rising edge capture of OSC_CG_ACK). To be read and cleared by DM after exiting WFI as a status signal distinguishing the case where WFI was entered and the clock was stopped, then exited with a wakeup (this bit will be set) from the case where an interrupt or other event caused the WFI sequence to stop and the HFXOSC was never stopped. (access R/W1TC)
  [28] SLEEP_STATUS_MAIN_DS_PROXY — Set when the main domain deep sleep power on reset / power domain off is activated. (rising edge detect of am62_wkup_ctrl_mmr.wkup_0.DS_MAIN_por_pdoff_ft_out_ipcfg). This will be checked by the ROM on TIFS upon exiting from reset to determine if it is a power on reset or exiting deep sleep. (access R/W1TC)
  [8] SLEEP_STATUS_MAIN_RESETSTATZ_PROXY ro — Reflects the status of the main domain resetz signal Field values (others are reserved): 1'b0 - Main Domain In Reset 1'b1 - Main Domain Out of Reset
0x1A418 CFG0_DS_MAGIC_WORD_PROXY
  [31:0] DS_MAGIC_WORD_DS_MAGIC_WORD_PROXY — Magic Word Indicating State of Deep Sleep
0x1A420 CFG0_DS_MAIN_PROXY reset 0xF
  [3:0] DS_MAIN_POR_PDOFF_PROXY — Signal Puts main SMS, DebugSS and MainIP Power Domains into Power Off state, and asserts Main Power On Reset. Field values (others are reserved): 4'b0110 - Off 4'b1111 - On
0x1A440 CFG0_DS_DM_RESET_PROXY reset 0xF
  [3:0] DS_DM_RESET_MASK_PROXY — Signal used to mask main domain resets from Device Manager / Wakeup and MCU Ips Field values (others are reserved): 4'b0110 - Masked 4'b1111 - UnMasked
0x1A460 CFG0_DS_USB0_RESET_PROXY reset 0xF
  [3:0] DS_USB0_RESET_MASK_PROXY — Signal used to block reset to the USBSS0 Field values (others are reserved): 4'b0110 - Masked 4'b1111 - UnMasked
0x1A464 CFG0_DS_USB1_RESET_PROXY reset 0xF
  [3:0] DS_USB1_RESET_MASK_PROXY — Signal used to block reset to the USBSS1 Field values (others are reserved): 4'b0110 - Masked 4'b1111 - UnMasked
0x1A480 CFG0_DM_CLKSTOP_EN_PROXY
  [17] DM_CLKSTOP_EN_EN_17_PROXY — WKUP DMTIMER1 Participation in Clockstop Req Group Field values (others are reserved): 1'b0 - Not Participating in Clockstop Override Group. DM_CLKSTOP_ACK.17 always reads '1' 1'b1 - Participating in Clockstop Override Group. DM_CLKSTOP_ACK.17 reflects the IP clockstop_ack
  [16] DM_CLKSTOP_EN_EN_16_PROXY — WKUP DMTIMER0 Participation in Clockstop Req Group Field values (others are reserved): 1'b0 - Not Participating in Clockstop Override Group. DM_CLKSTOP_ACK.16 always reads '1' 1'b1 - Participating in Clockstop Override Group. DM_CLKSTOP_ACK.16 reflects the IP clockstop_ack
  [3] DM_CLKSTOP_EN_EN_3_PROXY — WKUP UART0 Participation in Clockstop Req Group Field values (others are reserved): 1'b0 - Not Participating in Clockstop Override Group. DM_CLKSTOP_ACK.3 always reads '1' 1'b1 - Participating in Clockstop Override Group. DM_CLKSTOP_ACK.3 reflects the IP clockstop_ack
  [0] DM_CLKSTOP_EN_EN_0_PROXY — WKUP I2C0 Participation in Clockstop Req Group Field values (others are reserved): 1'b0 - Not Participating in Clockstop Override Group. DM_CLKSTOP_ACK.0 always reads '1' 1'b1 - Participating in Clockstop Override Group. DM_CLKSTOP_ACK.0 reflects the IP clockstop_ack
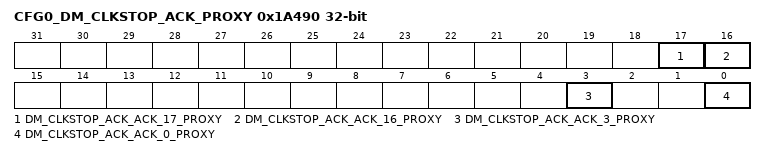
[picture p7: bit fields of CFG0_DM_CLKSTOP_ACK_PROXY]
0x1A490 CFG0_DM_CLKSTOP_ACK_PROXY ro
  [17] DM_CLKSTOP_ACK_ACK_17_PROXY — WKUP DMTIMER1 Clockstop Ack Status Field values (others are reserved): 1'b0 - IP is Participating in Clockstop Override Group, and IP clockstop_ack is 0 1'b1 - IP Is either not Participating in Clockstop Override Group, or IP has returned IP clockstop_ack
  [16] DM_CLKSTOP_ACK_ACK_16_PROXY — WKUP DMTIMER0 Clockstop Ack Status Field values (others are reserved): 1'b0 - IP is Participating in Clockstop Override Group, and IP clockstop_ack is 0 1'b1 - IP Is either not Participating in Clockstop Override Group, or IP has returned IP clockstop_ack
  [3] DM_CLKSTOP_ACK_ACK_3_PROXY — WKUP UART0 Clockstop Ack Status Field values (others are reserved): 1'b0 - IP is Participating in Clockstop Override Group, and IP clockstop_ack is 0 1'b1 - IP Is either not Participating in Clockstop Override Group, or IP has returned IP clockstop_ack
  [0] DM_CLKSTOP_ACK_ACK_0_PROXY — WKUP I2C0 Clockstop Ack Status Field values (others are reserved): 1'b0 - IP is Participating in Clockstop Override Group, and IP clockstop_ack is 0 1'b1 - IP Is either not Participating in Clockstop Override Group, or IP has returned IP clockstop_ack
0x1A4A0 CFG0_DM_GRP_CLKSTOP_REQ_PROXY
  [0] DM_GRP_CLKSTOP_REQ_REQ_PROXY — Assertion of Clockstop Req to IPs participating in Clockstop Req Group Field values (others are reserved): 1'b0 - Deassert CLKSTOP Req to all IPs participating in Clockstop Override Group 1'b1 - Assert CLKSTOP Req to all IPs participating in Clockstop Override Group
0x1A4A4 CFG0_DM_GRP_CLKSTOP_ACK_PROXY ro
  [0] DM_GRP_CLKSTOP_ACK_ACK_PROXY — Status of IPs Participating in Clockstop Ack Group. If DM_CLKSTOP_EN is 0 (no IPs participating) this bit always reads 1. Field values (others are reserved): 1'b0 - At least one IP participating in Clockstop Override has not returned Ack 1'b1 - All IPs that are participating in Clockstop Override have returned Ack
0x1A500 CFG0_DEVICE_TYPE_PROXY ro
  [7:4] DEVICE_TYPE_SMS_DEV_TYPE_PROXY
{0x1B100+4i} CFG0_CLAIMREG_P6_R{i} (i=0..10)
  [31:0] CLAIMREG_P6_R{i} — Claim bits for Partition 6
0x1C100 CFG0_BACKUP_REG
  [31:0] BACKUP_DATA — Storage for Backup Data During Deep Sleep
{0x1D100+4i} CFG0_CLAIMREG_P7_R{i}_READONLY ro (i=0..2)
  [31:0] CLAIMREG_P7_R{i}_READONLY — Claim bits for Partition 7
0x1E100 CFG0_BACKUP_REG_PROXY
  [31:0] BACKUP_DATA_PROXY — Storage for Backup Data During Deep Sleep
{0x1F100+4i} CFG0_CLAIMREG_P7_R{i} (i=0..2)
  [31:0] CLAIMREG_P7_R{i} — Claim bits for Partition 7
